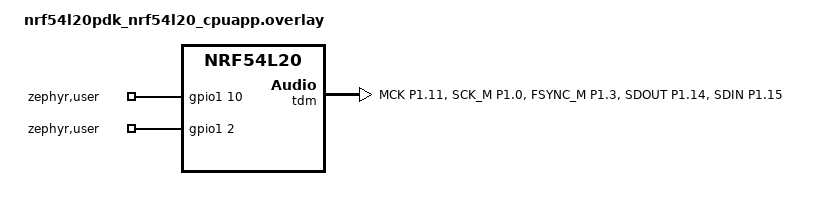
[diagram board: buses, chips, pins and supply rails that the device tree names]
/*
 * Copyright (c) 2025 Nordic Semiconductor ASA
 *
 * SPDX-License-Identifier: LicenseRef-Nordic-5-Clause
 */

/* i2s-node0 is the transmitter/receiver */

/ {
	aliases {
		i2s-node0 = &tdm;
	};

	zephyr,user {
		gpios = <&gpio1 10 GPIO_ACTIVE_HIGH>,  /* Connect with I2C_MCK */
				<&gpio1 2 GPIO_ACTIVE_HIGH>;  /* Connect with I2S_LRCK_M */
	};	
};

&pinctrl {
	tdm_default_alt: tdm_default_alt {
		group1 {
			psels =  <NRF_PSEL(TDM_MCK, 1, 11)>,
				<NRF_PSEL(TDM_SCK_M, 1, 0)>,
				<NRF_PSEL(TDM_FSYNC_M, 1, 3)>,
				<NRF_PSEL(TDM_SDOUT, 1, 14)>,  /* I2S_SDOUT connected with I2S_SDIN */
				<NRF_PSEL(TDM_SDIN, 1, 15)>;
		};
	};
};

&tdm {
	status = "okay";
	pinctrl-0 = <&tdm_default_alt>;
	pinctrl-names = "default";
	mck-frequency = <32000>;
};
